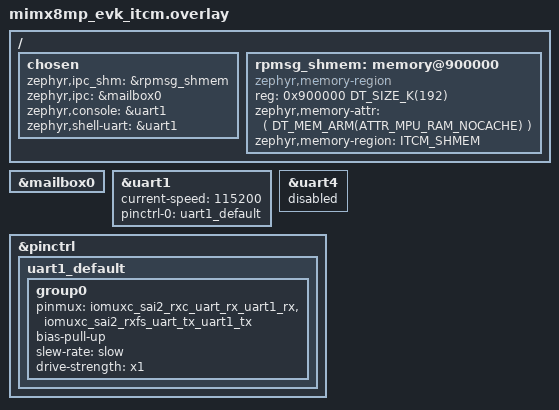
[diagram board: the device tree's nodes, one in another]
/*
 * Copyright 2023 NXP
 *
 * SPDX-License-Identifier: Apache-2.0
 */

#include <zephyr/dt-bindings/memory-attr/memory-attr-arm.h>

/ {
	chosen {
		zephyr,ipc_shm = &rpmsg_shmem;
		zephyr,ipc = &mailbox0;

		zephyr,console = &uart1;
		zephyr,shell-uart = &uart1;
	};

	rpmsg_shmem: memory@900000 {
		compatible = "zephyr,memory-region", "arm,itcm";
		reg = <0x900000 DT_SIZE_K(192)>;
		zephyr,memory-attr = <( DT_MEM_ARM(ATTR_MPU_RAM_NOCACHE) )>;
		zephyr,memory-region="ITCM_SHMEM";
	};
};

&mailbox0 {
	status = "okay";
};

&uart1 {
	status = "okay";
	current-speed = <115200>;
	pinctrl-0 = <&uart1_default>;
	pinctrl-names = "default";
};

&uart4 {
	status = "disabled";
};

&pinctrl {
	uart1_default: uart1_default {
		group0 {
			pinmux = <&iomuxc_sai2_rxc_uart_rx_uart1_rx>,
				<&iomuxc_sai2_rxfs_uart_tx_uart1_tx>;
			bias-pull-up;
			slew-rate = "slow";
			drive-strength = "x1";
		};
	};

};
